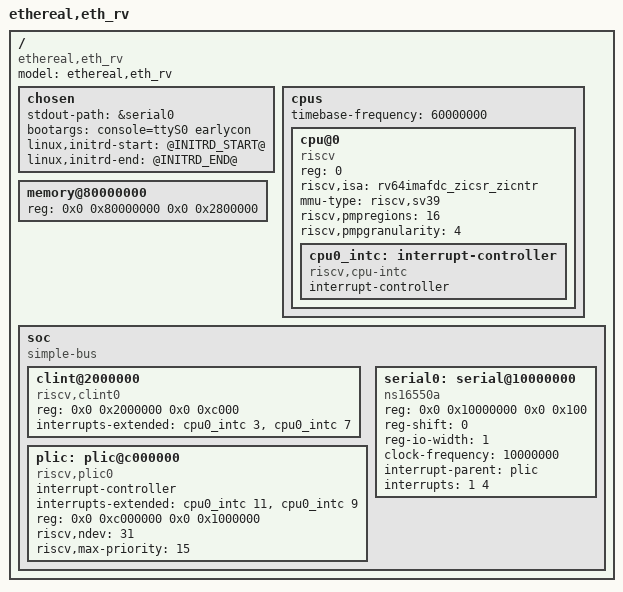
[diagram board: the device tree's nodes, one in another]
/* SPDX-License-Identifier: MIT
 *
 * eth_rv Linux device tree (E2-RV2 increment 7, S4: OpenSBI -> Linux).
 *
 * This is the DT the S4 boot uses on BOTH sides of the DiffTest: the firmware
 * finds it through a1 (the BootROM's device tree pointer) and the harness hands
 * the same blob to Spike with `--dtb=`. It is a separate file from eth_rv.dts on
 * purpose: eth_rv.dts is the *DiffTest corpus* profile (1 MiB window, DTB at
 * 0x8000_2000 right above the corpus image) and is pinned by test_rv_platform.py
 * against core.yaml; this file is the *Linux boot* profile (40 MiB window, kernel
 * at 0x8020_0000, DTB at the stock FW_JUMP_FDT_ADDR slot 0x8220_0000, initrd in
 * /chosen), which no corpus program can use.
 *
 * TEMPLATE: the two initrd addresses are `@INITRD_START@` / `@INITRD_END@` tokens.
 * They depend on the initramfs size, so verif/eth_rv/build_linux_boot.py
 * substitutes them and compiles the result into generated/rv_difftest/s4/
 * (the compiled blob is a build output; this file is the checked-in source).
 * Placement rule (shared with the RTL loader and Spike's own `--initrd`):
 *
 *     initrd_end   = RAM_BASE + ram_window_bytes - 0x1000
 *     initrd_start = initrd_end - <initramfs size>
 *
 * WHAT IS REAL HERE (and matches ethereal-shell/core.yaml + rv_platform.py)
 *   - memory @ 0x8000_0000, 40 MiB: the S4 window (`linux_ram_window_bytes`).
 *     Kernel `Image` (text_offset 0x200000 = FW_JUMP_OFFSET) 0x8020_0000..
 *     0x817D_6000, firmware 0x8000_0000..0x8004_2000, DTB 0x8220_0000.
 *   - clint @ 0x0200_0000: eth_rv_clint (msip/mtimecmp/mtime), the hart's
 *     M-mode timer/software source; S-mode timer interrupts come from OpenSBI's
 *     non-`sstc` path (`mtimecmp` + `mip.STIP`), which is why no `sstc` is
 *     declared below (the hart has no `stimecmp`).
 *   - plic @ 0x0C00_0000: eth_rv_plic, 31 sources, 4-bit priorities; the M and S
 *     contexts are declared per hart in Spike's order, so the S context is the
 *     hart's `mip.SEIP`.
 *   - serial @ 0x1000_0000: eth_rv_uart (ns16550a, reg-shift 0, 1-byte
 *     registers, source 1 level-triggered). `clock-frequency` is the only
 *     property a Linux 8250_of/earlycon probe insists on: it is set to the
 *     DiffTest timebase (10 MHz), which is what Spike's own auto-generated DTS
 *     emits for this UART. It is a placeholder, not a board number: neither the
 *     DUT's UART nor Spike's ns16550 model turns the divisor into a bit rate.
 *   - cpu @ 0: rv64imafdc_zicsr_zicntr, Sv39, one hart.
 *
 * WHAT ELSE IS DELIBERATELY ABSENT
 *   - No `sstc`, no IMSIC/APLIC, no cache/CMO properties, no Svadu/PBMTE, no
 *     Zicclsm (see rv_platform.py for the same list): a DT that claims more
 *     changes what the kernel is allowed to assume. Alpine's kernel has
 *     CONFIG_RISCV_ISA_FALLBACK=y, so every absent optional extension is one the
 *     kernel will simply not use.
 *   - No `riscv,isa-extensions`: the legacy `riscv,isa` string is what the S3/S5
 *     contract already pins, and it is what Spike parses for its own ISA.
 *
 * BOUNDARY
 *   `timebase-frequency` / `clock-frequency` are DiffTest cadence placeholders
 *   (the CLINT advances on the instruction cadence, Spike derives 10 MHz from
 *   CPU_HZ/INSNS_PER_RTC_TICK); software that turns them into seconds is out of
 *   contract until the SoC has a real tick source (E2-RV2 G9).
 */

/dts-v1/;

/ {
	#address-cells = <2>;
	#size-cells = <2>;
	compatible = "ethereal,eth_rv";
	model = "ethereal,eth_rv";

	chosen {
		stdout-path = &serial0;
		bootargs = "console=ttyS0 earlycon";
		/* The initramfs the S4 runner loads at these addresses (fw_jump
		 * passes only a0/a1, so this is the only handoff route). */
		linux,initrd-start = <@INITRD_START@>;
		linux,initrd-end = <@INITRD_END@>;
	};

	cpus {
		#address-cells = <1>;
		#size-cells = <0>;
		/* DiffTest placeholder, and the value the golden is run with: the kernel's
		 * HZ=1000 tick is 1 ms, i.e. `timebase-frequency / 1000` mtime ticks. With
		 * the S4 CLINT cadence (`mtime` 1:1 with the simulation clock) a 130 kHz
		 * timebase makes a tick 130 cycles long — a tick storm the kernel cannot
		 * make progress under: the boot deadlocks right after `Run /init as init
		 * process` in *Spike* too (reproduced) and never arms a timer in the RTL.
		 * 10 MHz gives 10,000 cycles (~1,700 instructions at the measured IPC) per
		 * tick, which boots to the milestone on both sides. It is also what Spike's
		 * own auto-generated DTS used as its placeholder, so no golden comparison
		 * changes meaning when a board swaps in the real SoC clock. */
		/* The mtime cadence is 1:1 with simulation CYCLES in this build, so the
		 * declared frequency is the simulation clock: it must be high enough that a
		 * HZ=1000 tick (freq/1000 cycles) is long compared with the tick handler,
		 * or the kernel spends all its time in the timer path and makes no forward
		 * progress (measured: 10 MHz => one interrupt per ~10,500 cycles, 18k traps,
		 * console frozen). 60 MHz puts a tick at ~60k cycles, which at this core's
		 * ~0.17 IPC is roughly Spike's 10,000-instruction tick. A board build
		 * replaces this with the real SoC clock. */
		timebase-frequency = <60000000>;

		cpu@0 {
			device_type = "cpu";
			compatible = "riscv";
			reg = <0>;
			status = "okay";
			riscv,isa = "rv64imafdc_zicsr_zicntr";
			mmu-type = "riscv,sv39";
			/* The hart HAS 16 PMP entries (`eth_rv_core` stores pmpcfg0..15 and
			 * pmpaddr0..15; `cor_pmp` pins that storage against Spike). Spike reads
			 * these two properties out of the DTB and they OVERRIDE its
			 * `--pmpregions` default: with them absent the golden runs with
			 * `n_pmp = 0` (riscv/dts.cc `fdt_parse_pmp_num` returns -ENODEV and
			 * sim.cc falls back to 0), so OpenSBI's `csrw pmpcfg0` probe traps with
			 * cause 2 on the Spike side only and the two sides' firmware boots take
			 * different paths ("PMP Count: 0" vs 16 in the banner). The values are
			 * Spike's own auto-DTS values, which is what the corpus's
			 * `dtb=spike-auto` runs have always used. */
			riscv,pmpregions = <16>;
			riscv,pmpgranularity = <4>;

			cpu0_intc: interrupt-controller {
				#interrupt-cells = <1>;
				interrupt-controller;
				compatible = "riscv,cpu-intc";
			};
		};
	};

	memory@80000000 {
		device_type = "memory";
		reg = <0x0 0x80000000 0x0 0x2800000>;
	};

	soc {
		#address-cells = <2>;
		#size-cells = <2>;
		compatible = "simple-bus";
		ranges;

		clint@2000000 {
			compatible = "riscv,clint0";
			reg = <0x0 0x2000000 0x0 0xc000>;
			interrupts-extended = <&cpu0_intc 3 &cpu0_intc 7>;
		};

		plic: plic@c000000 {
			compatible = "riscv,plic0";
			#address-cells = <0>;
			#interrupt-cells = <1>;
			interrupt-controller;
			interrupts-extended = <&cpu0_intc 11 &cpu0_intc 9>;
			reg = <0x0 0xc000000 0x0 0x1000000>;
			riscv,ndev = <31>;
			riscv,max-priority = <15>;
		};

		serial0: serial@10000000 {
			compatible = "ns16550a";
			reg = <0x0 0x10000000 0x0 0x100>;
			reg-shift = <0>;
			reg-io-width = <1>;
			clock-frequency = <10000000>;
			interrupt-parent = <&plic>;
			interrupts = <1 4>;
		};
	};
};
